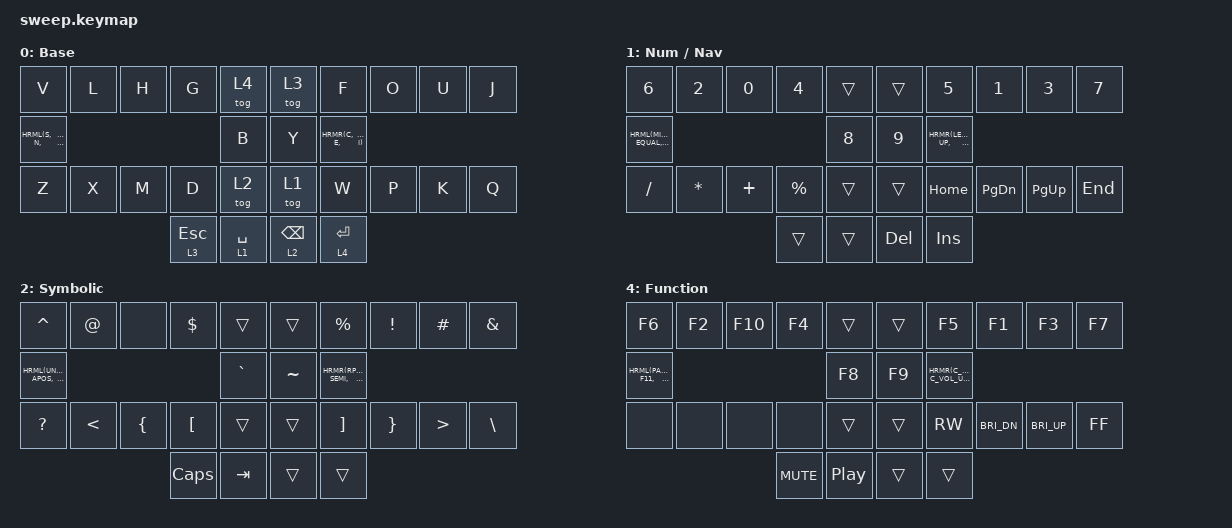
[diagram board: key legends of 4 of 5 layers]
#include <behaviors.dtsi>
#include <dt-bindings/zmk/keys.h>
#include <dt-bindings/zmk/bt.h>


#define ZMK_POINTING_DEFAULT_MOVE_VAL 1500
#define ZMK_POINTING_DEFAULT_SCRL_VAL 25

#include <dt-bindings/zmk/pointing.h>

&mmv {
    time-to-max-speed-ms = <500>;
    acceleration-exponent = <1>;
};

#define MMV_LEFT &mmv MOVE_LEFT
#define MMV_DOWN &mmv MOVE_DOWN
#define MMV_UP &mmv MOVE_UP
#define MMV_RIGHT &mmv MOVE_RIGHT

&msc {
    time-to-max-speed-ms = <50>;
    acceleration-exponent = <1>;
};

#define MSC_LEFT &msc SCRL_LEFT
#define MSC_DOWN &msc SCRL_DOWN
#define MSC_UP &msc SCRL_UP
#define MSC_RIGHT &msc SCRL_RIGHT


#define HRML(k1,k2,k3,k4) &ht LGUI k1  &ht LALT k2  &ht LCTRL k3  &ht LSHFT k4
#define HRMR(k1,k2,k3,k4) &ht RSHFT k1  &ht RCTRL k2  &ht RALT k3  &ht RGUI k4

#define KM_SEL(n) &bt BT_SEL n
#define KM_BRIDN &kp C_BRI_DN
#define KM_BRIUP &kp C_BRI_UP


&lt {
    flavor = "tap-preferred";
    tapping-term-ms = <200>;
    quick-tap-ms = <200>;
    require-prior-idle-ms = <100>;
};

/ {
    behaviors {
        ht: hold_tap {
            compatible = "zmk,behavior-hold-tap";
            #binding-cells = <2>;
            flavor = "tap-preferred";
            tapping-term-ms = <200>;
            quick-tap-ms = <200>;
            require-prior-idle-ms = <100>;
            bindings = <&kp>, <&kp>;
        };
    };

    keymap {
        compatible = "zmk,keymap";
        default_layer {
            display-name = "Base";
            bindings = <
        //╭──────────┬──────────┬──────────┬──────────┬──────────╮   ╭──────────┬──────────┬──────────┬──────────┬──────────╮
        //│  V       │  L       │  H       │  G       │  Fn      │   │  Mouse   │  F       │  O       │  U       │  J       │
            &kp V      &kp L      &kp H      &kp G      &tog 4         &tog 3     &kp F      &kp O      &kp U      &kp J
        //├──────────┼──────────┼──────────┼──────────┼──────────┤   ├──────────┼──────────┼──────────┼──────────┼──────────┤
        //│  S       │  R       │  N       │  T       │  B       │   │  Y       │  C       │  A       │  E       │  I       │
            HRML(S,        R,         N,         T)     &kp B          &kp Y      HRMR(C,        A,         E,         I)
        //├──────────┼──────────┼──────────┼──────────┼──────────┤   ├──────────┼──────────┼──────────┼──────────┼──────────┤
        //│  Z       │  X       │  M       │  D       │  Sym     │   │  Num/Nav │  W       │   P      │  K       │  Q       │
            &kp Z      &kp X      &kp M      &kp D      &tog 2         &tog 1    &kp W      &kp P      &kp K      &kp Q    
        //╰──────────┴──────────┴──────────┼──────────┼──────────┤   ├──────────┼──────────┼──────────┴──────────┴──────────╯
                                            &lt 3 ESC  &lt 1 SPACE    &lt 2 BSPC &lt 4 ENTER
        //                                 ╰──────────┴──────────╯   ╰──────────┴──────────╯
            >;
        };

        num_layer {
            display-name = "Num / Nav";
            bindings = <
        //╭──────────┬──────────┬──────────┬──────────┬──────────╮   ╭──────────┬──────────┬──────────┬──────────┬──────────╮
        //│  6       │  2       │  0       │  4       │          │   │          │  5       │  1       │  3       │  7       │
            &kp N6     &kp N2     &kp N0     &kp N4     &trans         &trans     &kp N5     &kp N1     &kp N3     &kp N7
        //├──────────┼──────────┼──────────┼──────────┼──────────┤   ├──────────┼──────────┼──────────┼──────────┼──────────┤
        //│  -       │  .       │  =       │  ,       │  8       │   │  9       │  Left    │  Down    │  Up      │  Right   │
           HRML(MINUS,    DOT,       EQUAL,     COMMA)  &kp N8         &kp N9     HRMR(LEFT,    DOWN,        UP,      RIGHT)
        //├──────────┼──────────┼──────────┼──────────┼──────────┤   ├──────────┼──────────┼──────────┼──────────┼──────────┤
        //│  /       │  *       │  +       │  %       │          │   │          │  Home    │  PgDn    │  PgUp    │  End     │
            &kp SLASH  &kp STAR   &kp PLUS   &kp PRCNT  &trans         &trans     &kp HOME   &kp PG_DN  &kp PG_UP  &kp END
        //╰──────────┴──────────┴──────────┼──────────┼──────────┤   ├──────────┼──────────┼──────────┴──────────┴──────────╯
                                             &trans     &trans         &kp DEL    &kp INS         
        //                                 ╰──────────┴──────────╯   ╰──────────┴──────────╯
            >;
        };

        sym_layer {
            display-name = "Symbolic";
            bindings = <
        //╭──────────┬──────────┬──────────┬──────────┬──────────╮   ╭──────────┬──────────┬──────────┬──────────┬──────────╮
        //│  ^       │  @       │          │  $       │          │   │          │  %       │  !       │  #       │  &       │
            &kp CARET  &kp AT     &none      &kp DLLR   &trans         &trans     &kp PRCNT  &kp EXCL   &kp HASH   &kp AMPS
        //├──────────┼──────────┼──────────┼──────────┼──────────┤   ├──────────┼──────────┼──────────┼──────────┼──────────┤
        //│  _       │  :       │  '       │  (       │  `       │   │  ~       │  )       │  ;       │  ;       │  |       │
           HRML(UNDER,    COLON,      APOS,      LPAR)  &kp GRAVE      &kp TILDE  HRMR(RPAR,     DQT,       SEMI,      PIPE)
        //├──────────┼──────────┼──────────┼──────────┼──────────┤   ├──────────┼──────────┼──────────┼──────────┼──────────┤
        //│  ?       │  <       │  {       │  [       │          │   │          │  ]       │  }       │  >       │  \       │
            &kp QMARK  &kp LT     &kp LBRC   &kp LBKT   &trans         &trans     &kp RBKT   &kp RBRC   &kp GT     &kp BSLH
        //╰──────────┴──────────┴──────────┼──────────┼──────────┤   ├──────────┼──────────┼──────────┴──────────┴──────────╯
                                             &kp CAPS   &kp TAB        &trans     &trans
        //                                 ╰──────────┴──────────╯   ╰──────────┴──────────╯
            >;
        };

        mouse_layer {
            display-name = "Mouse";
            bindings = <
        //╭──────────┬──────────┬──────────┬──────────┬──────────╮   ╭──────────┬──────────┬──────────┬──────────┬──────────╮
        //│  BT CLR  │  BT 2    │  BT 0    │  BT 4    │          │   │          │  Back    │  BT 1    │  BT 3    │  Forward │
           &bt BT_CLR  KM_SEL(2)  KM_SEL(0)  KM_SEL(4)  &trans         &trans     &mkp MB4   KM_SEL(1)  KM_SEL(3)  &mkp MB5
        //├──────────┼──────────┼──────────┼──────────┼──────────┤   ├──────────┼──────────┼──────────┼──────────┼──────────┤
        //│  Undo    │  Cut     │  Copy    │  Paste   │  Redo    │   │ MidClick │  MvLeft  │  MvDown  │  MvUp    │  MvRight │
            &kp LC(Z)  &kp LC(X)  &kp LC(C)  &kp LC(V)  &kp LC(Y)      &mkp MCLK  MMV_LEFT   MMV_DOWN   MMV_UP     MMV_RIGHT
        //├──────────┼──────────┼──────────┼──────────┼──────────┤   ├──────────┼──────────┼──────────┼──────────┼──────────┤
        //│          │          │          │          │          │   │          │  MsLeft  │  MsDown  │  MsUp    │  MsRight │
            &none      &none      &none      &none      &trans         &trans     MSC_LEFT   MSC_DOWN   MSC_UP     MSC_RIGHT
        //╰──────────┴──────────┴──────────┼──────────┼──────────┤   ├──────────┼──────────┼──────────┴──────────┴──────────╯
                                             &trans     &trans         &mkp LCLK  &mkp RCLK
        //                                 ╰──────────┴──────────╯   ╰──────────┴──────────╯
            >;
        };

        fn_layer {
            display-name = "Function";
            bindings = <
        //╭──────────┬──────────┬──────────┬──────────┬──────────╮   ╭──────────┬──────────┬──────────┬──────────┬──────────╮
        //│  F6      │  F2      │  F10     │  F4      │          │   │          │  F5      │  F1      │  F3      │  F7      │
            &kp F6     &kp F2     &kp F10    &kp F4     &trans         &trans     &kp F5     &kp F1     &kp F3     &kp F7
        //├──────────┼──────────┼──────────┼──────────┼──────────┤   ├──────────┼──────────┼──────────┼──────────┼──────────┤
        //│  Break   │  F12     │  F11     │  PrScr   │  F8      │   │  F9      │  Prev    │  Vol -   │  Vol +   │  Next    │
    HRML(PAUSE_BREAK,      F12,       F11,      PSCRN)  &kp F8         &kp F9   HRMR(C_PREV, C_VOL_DN,  C_VOL_UP,  C_NEXT)
        //├──────────┼──────────┼──────────┼──────────┼──────────┤   ├──────────┼──────────┼──────────┼──────────┼──────────┤
        //│          │          │          │          │          │   │          │  Rewind  │  Bri -   │  Bri +   │  Forward │
            &none      &none      &none      &none      &trans         &trans     &kp C_RW   KM_BRIDN   KM_BRIUP   &kp C_FF
        //╰──────────┴──────────┴──────────┼──────────┼──────────┤   ├──────────┼──────────┼──────────┴──────────┴──────────╯
                                            &kp C_MUTE  &kp C_PP       &trans     &trans
        //                                 ╰──────────┴──────────╯   ╰──────────┴──────────╯
            >;
        };
    };
};
